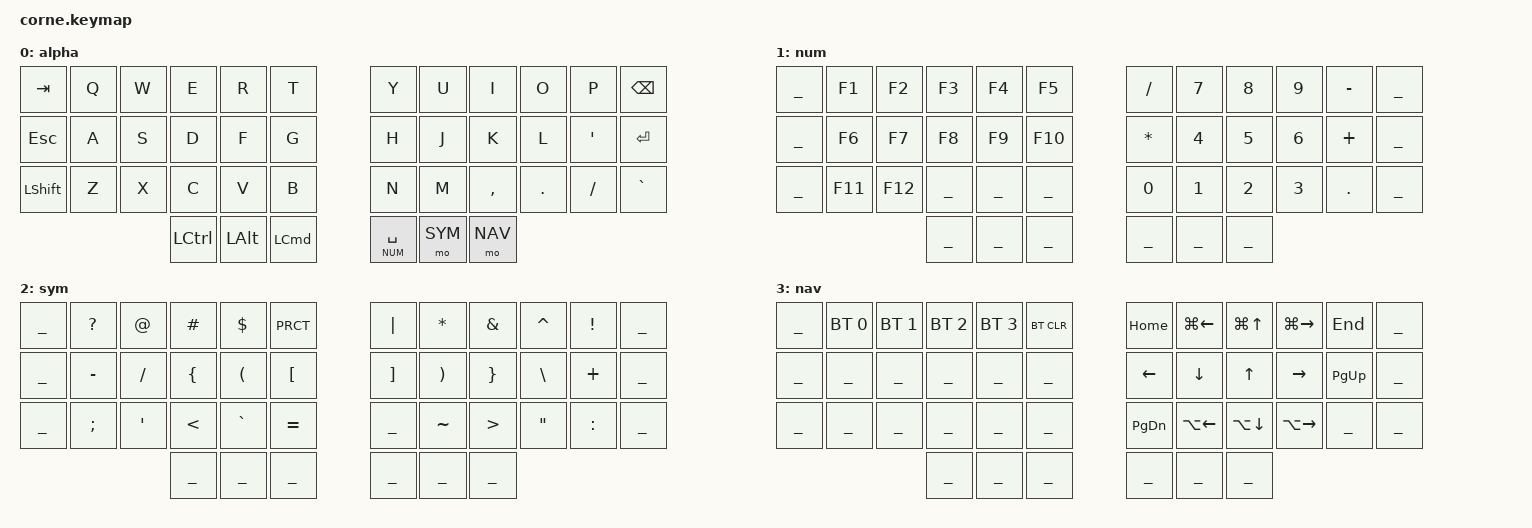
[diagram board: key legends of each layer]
/*
 * Copyright (c) 2020 The ZMK Contributors
 *
 * SPDX-License-Identifier: MIT
 */

#include <behaviors.dtsi>
#include <dt-bindings/zmk/keys.h>
#include <dt-bindings/zmk/bt.h>

#define ALPHA 0
#define NUM   1
#define SYM   2
#define NAV   3

/ {
  behaviors {
    hm: homerow_shift_esc {
      compatible = "zmk,behavior-hold-tap";
      #binding-cells = <2>;
      flavor = "tap-preferred";
      tapping-term-ms = <175>;
      quick-tap-ms = <150>;
      bindings = <&kp>, <&kp>;
    };
    lt_bal: layer_tap_balanced {
      compatible = "zmk,behavior-hold-tap";
      #binding-cells = <2>;
      flavor = "balanced";
      tapping-term-ms = <175>;
      quick-tap-ms = <150>;
      bindings = <&mo>, <&kp>;
    };
  };

  combos {
    compatible = "zmk,combos";
    caps {
      bindings = <&caps_word>;
      key-positions = <24 35>;
    };
  };

  keymap {
    compatible = "zmk,keymap";

    alpha {
      bindings = <
        &kp TAB         &kp Q    &kp W    &kp E    &kp R    &kp T        &kp Y              &kp U    &kp I     &kp O    &kp P     &kp BSPC
        &kp ESC         &kp A    &kp S    &kp D    &kp F    &kp G        &kp H              &kp J    &kp K     &kp L    &kp SQT   &kp ENTER
        &kp LSHFT       &kp Z    &kp X    &kp C    &kp V    &kp B        &kp N              &kp M    &kp COMMA &kp DOT  &kp FSLH  &kp GRAVE
        &kp LCTRL &kp LALT &kp LCMD                                      &lt_bal NUM SPACE  &mo SYM  &mo NAV
      >;
      label = "alpha";
    };

    num {
      bindings = <
        ___  &kp F1   &kp F2   &kp F3   &kp F4   &kp F5       &kp FSLH  &kp N7   &kp N8   &kp N9   &kp MINUS  ___
        ___  &kp F6   &kp F7   &kp F8   &kp F9   &kp F10      &kp STAR  &kp N4   &kp N5   &kp N6   &kp PLUS   ___
        ___  &kp F11  &kp F12  ___   ___   ___       &kp N0    &kp N1   &kp N2   &kp N3   &kp DOT    ___
        ___  ___   ___                                  ___    ___   ___
      >;
      label = "num";
    };

    sym {
      bindings = <
        ___  &kp QMARK  &kp AT    &kp HASH  &kp DLLR   &kp PRCT     &kp PIPE   &kp STAR   &kp AMPS  &kp CARET  &kp EXCL   ___
        ___  &kp MINUS  &kp FSLH  &kp LBRC  &kp LPAR   &kp LBKT     &kp RBKT   &kp RPAR   &kp RBRC  &kp BSLH   &kp PLUS   ___
        ___  &kp SEMI   &kp SQT   &kp LT    &kp GRAVE  &kp EQUAL    &kp UNDER  &kp TILDE  &kp GT    &kp DQT    &kp COLON  ___
        ___  ___     ___                                      ___     ___     ___
      >;
      label = "sym";
    };

    nav {
      bindings = <
        ___  &bt BT_SEL 0  &bt BT_SEL 1  &bt BT_SEL 2  &bt BT_SEL 3  &bt BT_CLR    &kp HOME   &kp LG(LEFT)  &kp LG(UP)    &kp LG(RIGHT)  &kp END     ___
        ___  ___        ___        ___        ___        ___        &kp LEFT   &kp DOWN      &kp UP        &kp RIGHT      &kp PG_UP   ___
        ___  ___        ___        ___        ___        ___        &kp PG_DN  &kp LA(LEFT)  &kp LA(DOWN)  &kp LA(RIGHT)  ___      ___
        ___  ___        ___                                                  ___     ___        ___
      >;
      label = "nav";
    };
  };
};
